# SAC0_455.0.8_config1 register map
Vendor: Texas Instruments
Peripheral module from a debugger description file (folder msp430).
Registers are 16-bit, read-write, no defined reset value unless marked. A register's access mark holds for its fields unless they carry their own. Offsets are as the file gives them; lines under a group give offsets from that group; [hi:lo] are bit positions; {n}, {i} and the like mark numbered series; 'fields as' and 'values as' point back to an identical list; <NAME> marks a mode.

## SAC0
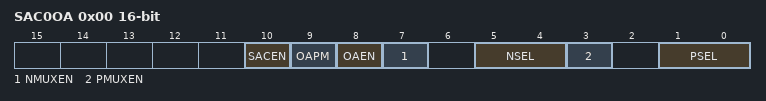
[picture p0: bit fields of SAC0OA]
0x00 SAC0OA — SAC OA Control Register
  [10] SACEN — SAC Enable selection
    0=SAC all modules are disabled, then the SAC output high impedance; 1=SAC all modules are enabled, normal mode
  [9] OAPM — SAC OA power mode selection
    0=High speed and high power; 1=Llow speed and low power
  [8] OAEN — SAC OA Enable selection
    0=SAC OA is disabled, then the SAC OA output high impedance; 1=SAC OA is enabled, normal mode
  [7] NMUXEN — SAC Negative input MUX controL
    0=All negative input sources are disconnected to OA negative port; 1=All negative input sources are connected to OA negative port
  [5:4] NSEL — SAC OA Negative input source selection
    0=External source selected; 1=PGA source selected; 2=Device Specific
  [3] PMUXEN — SAC Positive input MUX control.
    0=All positive input sources are disconnected to OA positive port; 1=All positive input sources are connected to OA positive port
  [1:0] PSEL — SAC OA Positive input source selection
    0=External source selected; 1=12-bit reference DAC source selected; 2=Pair OA source selected
